AUTOSAR XML (schema 4.0)
standard types defined: float32, float64, sint16, sint32, sint8, uint16, uint32, uint8, void, boolean
package /ImplDataTypes
  7 x impl type, all with category=TYPE_REFERENCE, type-emitter=RTE:
    Impl_IoPositionSensorReadingType: implementation-data-type=uint8
    Impl_IoWeightSensorReadingType: implementation-data-type=uint16
    Impl_MultiStateBtnType: implementation-data-type=uint8
    Impl_SeatModeBtnType: implementation-data-type=uint8
    Impl_SensorPositionType: implementation-data-type=uint8
    Impl_SensorWeightType: implementation-data-type=uint8
    Impl_StepMotorStepType: implementation-data-type=Impl_MultiStateBtnType
package /MappingSets
  data type mapping set MappingSet: mode-request-type-map{implementation-data-type=uint8, mode-group=SeatCtrlMode}
package /PortInterfaces/ClientServer
  6 x client server interface:
    CsIf_IoGetSensorPosition
      operation Opr_IOGet
        arg Arg_position: type=Impl_IoPositionSensorReadingType, direction=OUT
    CsIf_IoGetSensorWeight
      operation Opr_IOGet
        arg Arg_weight: type=Impl_IoWeightSensorReadingType, direction=OUT
    CsIf_IoSetMotor
      operation Opr_IOSetForward
      operation Opr_IOSetReverse
    CsIf_PositionSensor
      operation Opr_GetPosition
        arg Arg_position: type=Impl_SensorPositionType, direction=OUT
    CsIf_StepMotor
      operation Opr_HeightMotor_Move
        arg Arg_Step: type=Impl_StepMotorStepType, direction=IN
      operation Opr_InclineMotor_Move
        arg Arg_Step: type=Impl_MultiStateBtnType, direction=IN
      operation Opr_SlideMotor_Move
        arg Arg_Step: type=Impl_StepMotorStepType, direction=IN
    CsIf_WeightSensor
      operation Opr_GetWeight
        arg Arg_Weight: type=Impl_SensorWeightType, direction=OUT
package /PortInterfaces/ModeSwitch
  mode switch interface MsIf_SeatCtrlMode
    mode group SeatCtrlMode: type=SeatCtrlMode
  mode declaration group SeatCtrlMode: category=ALPHABETIC_ORDER, initial-mode=INIT, on-transition-value=255
    mode AUTO
    mode INIT
    mode MANUAL
package /PortInterfaces/SenderReceiver
  sender receiver interface SrIf_SeatCtrlBtns
    data DE_HeightBtnState: type=Impl_MultiStateBtnType
    data DE_InclineBtnState: type=Impl_MultiStateBtnType
    data DE_SlideBtnState: type=Impl_MultiStateBtnType
  sender receiver interface SrIf_SeatCtrlData
    data DE_Hight: type=uint8
    data DE_Incline: type=uint8
    data DE_Slide: type=uint8
  sender receiver interface SrIf_SeatModeBtn
    data DE_SeatModeBtn: type=Impl_SeatModeBtnType
package /SoftwareComponents
  10 x swc implementation, all with programming-language=C, sw-version=1.0.0, vendor-id=255:
    Impl_SWC_HMI: behavior=Ibhv_SWC_HMI
      code-descriptors:
        code Code: artifact-descriptors=autosar-engineering-object={short-label=SWC.c, category=SWSRC}
      resource consumption ResourceConsumption
    Impl_SWC_HeightMotor: behavior=Ibhv_SWC_HeightMotor
      code-descriptors:
        code Code: artifact-descriptors=autosar-engineering-object={short-label=SWC.c, category=SWSRC}
      resource consumption ResourceConsumption
    Impl_SWC_HeightSensor: behavior=Ibhv_SWC_HeightSensor
      code-descriptors:
        code Code: artifact-descriptors=autosar-engineering-object={short-label=SWC.c, category=SWSRC}
      resource consumption ResourceConsumption
    Impl_SWC_InclineMotor: behavior=Ibhv_SWC_InclineMotor
      code-descriptors:
        code Code: artifact-descriptors=autosar-engineering-object={short-label=SWC.c, category=SWSRC}
      resource consumption ResourceConsumption
    Impl_SWC_InclineSensor: behavior=Ibhv_SWC_InclineSensor
      code-descriptors:
        code Code: artifact-descriptors=autosar-engineering-object={short-label=SWC.c, category=SWSRC}
      resource consumption ResourceConsumption
    Impl_SWC_IoHwAbs: behavior=Ibhv_SWC_IoHwAbs
      code-descriptors:
        code Code: artifact-descriptors=autosar-engineering-object={short-label=SWC.c, category=SWSRC}
      resource consumption ResourceConsumption
    Impl_SWC_SeatManager: behavior=Ibhv_SWC_SeatManager
      code-descriptors:
        code Code: artifact-descriptors=autosar-engineering-object={short-label=SWC.c, category=SWSRC}
      resource consumption ResourceConsumption
    Impl_SWC_SlideMotor: behavior=Ibhv_SWC_SlideMotor
      code-descriptors:
        code Code: artifact-descriptors=autosar-engineering-object={short-label=SWC.c, category=SWSRC}
      resource consumption ResourceConsumption
    Impl_SWC_SlideSensor: behavior=Ibhv_SWC_SlideSensor
      code-descriptors:
        code Code: artifact-descriptors=autosar-engineering-object={short-label=SWC.c, category=SWSRC}
      resource consumption ResourceConsumption
    Impl_SWC_WeightSensor: behavior=Ibhv_SWC_WeightSensor
      code-descriptors:
        code Code: artifact-descriptors=autosar-engineering-object={short-label=SWC.c, category=SWSRC}
      resource consumption ResourceConsumption
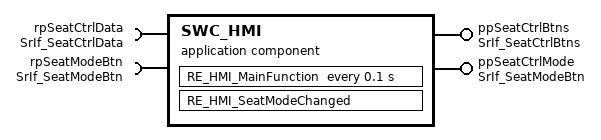
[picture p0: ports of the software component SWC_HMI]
  application sw component type SWC_HMI
    provide port ppSeatCtrlBtns: provided-interface=SrIf_SeatCtrlBtns
    provide port ppSeatCtrlMode: provided-interface=SrIf_SeatModeBtn
    require port rpSeatCtrlData: required-interface=SrIf_SeatCtrlData
    require port rpSeatModeBtn: required-interface=SrIf_SeatModeBtn
    behavior Ibhv_SWC_HMI: data-type-mapping=MappingSet, handle-termination-and-restart=NO-SUPPORT
      data received event DRE_rpSeatModeBtn_DE_SeatModeBtn: start-on-event=RE_HMI_SeatModeChanged, data=rpSeatModeBtn.DE_SeatModeBtn
      timing event TE_RE_HMI_MainFunction_100ms: start-on-event=RE_HMI_MainFunction, period=0.1
      runnable RE_HMI_MainFunction
        data-receive-point-by-arguments:
          access DRP_rpSeatCtrlData_DE_Hight: accessed-variable=rpSeatCtrlData.DE_Hight
          access DRP_rpSeatCtrlData_DE_Incline: accessed-variable=rpSeatCtrlData.DE_Incline
          access DRP_rpSeatCtrlData_DE_Slide: accessed-variable=rpSeatCtrlData.DE_Slide
        data-send-points:
          access DSP_ppSeatCtrlBtns_DE_HeightBtnState: accessed-variable=ppSeatCtrlBtns.DE_HeightBtnState
          access DSP_ppSeatCtrlBtns_DE_InclineBtnState: accessed-variable=ppSeatCtrlBtns.DE_InclineBtnState
          access DSP_ppSeatCtrlBtns_DE_SlideBtnState: accessed-variable=ppSeatCtrlBtns.DE_SlideBtnState
      runnable RE_HMI_SeatModeChanged
        data-receive-point-by-arguments:
          access DRP_rpSeatModeBtn_DE_SeatModeBtn: accessed-variable=rpSeatModeBtn.DE_SeatModeBtn
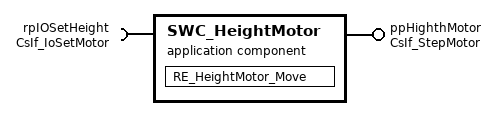
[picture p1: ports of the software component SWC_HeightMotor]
  application sw component type SWC_HeightMotor
    provide port ppHighthMotor: provided-interface=CsIf_StepMotor
    require port rpIOSetHeight: required-interface=CsIf_IoSetMotor
    behavior Ibhv_SWC_HeightMotor: data-type-mapping=MappingSet, handle-termination-and-restart=NO-SUPPORT
      operation invoked event OIE_ppHighthMotor_Opr_HeightMotor_Move: start-on-event=RE_HeightMotor_Move, operation=ppHighthMotor.Opr_HeightMotor_Move
      runnable RE_HeightMotor_Move
        sync call SCP_rpIOSetHeight_Opr_IOSetForward: operation=rpIOSetHeight.Opr_IOSetForward, timeout=0.0
        sync call SCP_rpIOSetHeight_Opr_IOSetReverse: operation=rpIOSetHeight.Opr_IOSetReverse, timeout=0.0
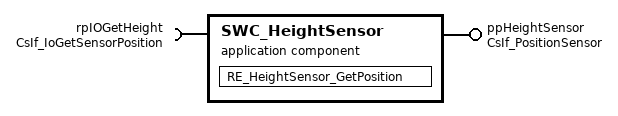
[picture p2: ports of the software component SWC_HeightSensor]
  application sw component type SWC_HeightSensor
    provide port ppHeightSensor: provided-interface=CsIf_PositionSensor
    require port rpIOGetHeight: required-interface=CsIf_IoGetSensorPosition
    behavior Ibhv_SWC_HeightSensor: data-type-mapping=MappingSet, handle-termination-and-restart=NO-SUPPORT
      operation invoked event OIE_ppHeightSensor_Opr_GetPosition: start-on-event=RE_HeightSensor_GetPosition, operation=ppHeightSensor.Opr_GetPosition
      runnable RE_HeightSensor_GetPosition
        sync call SCP_rpIoGetSensorPosition_Opr_IOGet: operation=rpIOGetHeight.Opr_IOGet, timeout=0.0
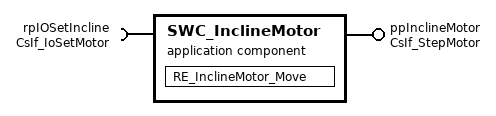
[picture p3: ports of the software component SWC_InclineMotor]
  application sw component type SWC_InclineMotor
    provide port ppInclineMotor: provided-interface=CsIf_StepMotor
    require port rpIOSetIncline: required-interface=CsIf_IoSetMotor
    behavior Ibhv_SWC_InclineMotor: data-type-mapping=MappingSet, handle-termination-and-restart=NO-SUPPORT
      operation invoked event OIE_ppInclineMotor_Opr_InclineMotor_Move: start-on-event=RE_InclineMotor_Move, operation=ppInclineMotor.Opr_InclineMotor_Move
      runnable RE_InclineMotor_Move
        sync call SCP_rpIOSetIncline_Opr_IOSetForward: operation=rpIOSetIncline.Opr_IOSetForward, timeout=0.0
        sync call SCP_rpIOSetIncline_Opr_IOSetReverse: operation=rpIOSetIncline.Opr_IOSetReverse, timeout=0.0
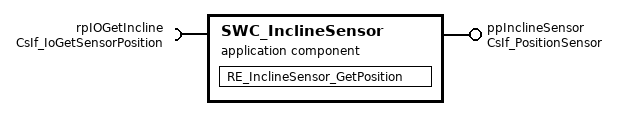
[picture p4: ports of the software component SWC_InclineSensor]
  application sw component type SWC_InclineSensor
    provide port ppInclineSensor: provided-interface=CsIf_PositionSensor
    require port rpIOGetIncline: required-interface=CsIf_IoGetSensorPosition
    behavior Ibhv_SWC_InclineSensor: data-type-mapping=MappingSet, handle-termination-and-restart=NO-SUPPORT
      operation invoked event OIE_ppInclineSensor_Opr_GetPosition: start-on-event=RE_InclineSensor_GetPosition, operation=ppInclineSensor.Opr_GetPosition
      runnable RE_InclineSensor_GetPosition
        sync call SCP_rpIOGetIncline_Opr_IOGet: operation=rpIOGetIncline.Opr_IOGet, timeout=0.0
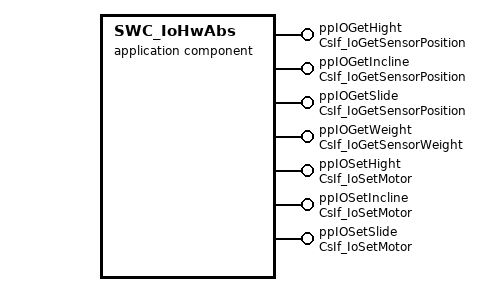
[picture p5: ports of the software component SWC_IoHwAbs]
  application sw component type SWC_IoHwAbs
    7 x provide port:
      ppIOGetHight: provided-interface=CsIf_IoGetSensorPosition
      ppIOGetIncline: provided-interface=CsIf_IoGetSensorPosition
      ppIOGetSlide: provided-interface=CsIf_IoGetSensorPosition
      ppIOGetWeight: provided-interface=CsIf_IoGetSensorWeight
      ppIOSetHight: provided-interface=CsIf_IoSetMotor
      ppIOSetIncline: provided-interface=CsIf_IoSetMotor
      ppIOSetSlide: provided-interface=CsIf_IoSetMotor
    behavior Ibhv_SWC_IoHwAbs: data-type-mapping=MappingSet, handle-termination-and-restart=NO-SUPPORT
      10 x operation invoked event:
        OIE_ppIOGetHight_Opr_IOGet: start-on-event=RE_IoHwAbs_ECUGet_Height, operation=ppIOGetHight.Opr_IOGet
        OIE_ppIOGetIncline_Opr_IOGet: start-on-event=RE_IoHwAbs_ECUGet_Incline, operation=ppIOGetIncline.Opr_IOGet
        OIE_ppIOGetSlide_Opr_IOGet: start-on-event=RE_IoHwAbs_ECUGet_Slide, operation=ppIOGetSlide.Opr_IOGet
        OIE_ppIOGetWeight_Opr_IOGet: start-on-event=RE_IoHwAbs_ECUGet_Weight, operation=ppIOGetWeight.Opr_IOGet
        OIE_ppIOSetHight_Opr_IOSetForward: start-on-event=RE_IoHwAbs_ECUSetForword_Height, operation=ppIOSetHight.Opr_IOSetForward
        OIE_ppIOSetHight_Opr_IOSetReverse: start-on-event=RE_IoHwAbs_ECUSetReverse_Height, operation=ppIOSetHight.Opr_IOSetReverse
        OIE_ppIOSetIncline_Opr_IOSetForward: start-on-event=RE_IoHwAbs_ECUSetForword_Incline, operation=ppIOSetIncline.Opr_IOSetForward
        OIE_ppIOSetIncline_Opr_IOSetReverse: start-on-event=RE_IoHwAbs_ECUSetReverse_Incline, operation=ppIOSetIncline.Opr_IOSetReverse
        OIE_ppIOSetSlide_Opr_IOSetForward: start-on-event=RE_IoHwAbs_ECUSetForword_Slide, operation=ppIOSetSlide.Opr_IOSetForward
        OIE_ppIOSetSlide_Opr_IOSetReverse: start-on-event=RE_IoHwAbs_ECUSetRevese_Slide, operation=ppIOSetSlide.Opr_IOSetReverse
      10 x runnable:
        RE_IoHwAbs_ECUGet_Height
        RE_IoHwAbs_ECUGet_Incline
        RE_IoHwAbs_ECUGet_Slide
        RE_IoHwAbs_ECUGet_Weight
        RE_IoHwAbs_ECUSetForword_Height
        RE_IoHwAbs_ECUSetForword_Incline
        RE_IoHwAbs_ECUSetForword_Slide
        RE_IoHwAbs_ECUSetReverse_Height
        RE_IoHwAbs_ECUSetReverse_Incline
        RE_IoHwAbs_ECUSetRevese_Slide
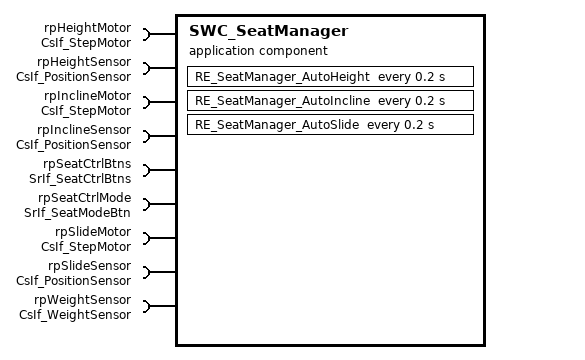
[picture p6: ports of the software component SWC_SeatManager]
  application sw component type SWC_SeatManager
    9 x require port:
      rpHeightMotor: required-interface=CsIf_StepMotor
      rpHeightSensor: required-interface=CsIf_PositionSensor
      rpInclineMotor: required-interface=CsIf_StepMotor
      rpInclineSensor: required-interface=CsIf_PositionSensor
      rpSeatCtrlBtns: required-interface=SrIf_SeatCtrlBtns
      rpSeatCtrlMode: required-interface=SrIf_SeatModeBtn
      rpSlideMotor: required-interface=CsIf_StepMotor
      rpSlideSensor: required-interface=CsIf_PositionSensor
      rpWeightSensor: required-interface=CsIf_WeightSensor
    behavior Ibhv_SWC_SeatManager: data-type-mapping=MappingSet, handle-termination-and-restart=NO-SUPPORT
      data received event DRE_rpSeatCtrlBtns_DE_HeightBtnState: start-on-event=RE_SeatManager_SetHeight, data=rpSeatCtrlBtns.DE_HeightBtnState
      data received event DRE_rpSeatCtrlBtns_DE_InclineBtnState: start-on-event=RE_SeatManager_SetIncline, data=rpSeatCtrlBtns.DE_InclineBtnState
      data received event DRE_rpSeatCtrlBtns_DE_SlideBtnState: start-on-event=RE_SeatManager_SetSlide, data=rpSeatCtrlBtns.DE_SlideBtnState
      timing event TE_RE_SeatManager_AutoHeight_200ms: start-on-event=RE_SeatManager_AutoHeight, period=0.2
      timing event TE_RE_SeatManager_AutoIncline_200ms: start-on-event=RE_SeatManager_AutoIncline, period=0.2
      timing event TE_RE_SeatManager_AutoSlide_200ms: start-on-event=RE_SeatManager_AutoSlide, period=0.2
      6 x runnable:
        RE_SeatManager_AutoHeight
          sync call SCP_rpHeightMotor_Opr_HeightMotor_Move: operation=rpHeightMotor.Opr_HeightMotor_Move, timeout=0.0
          sync call SCP_rpHeightSensor_Opr_GetPosition: operation=rpHeightSensor.Opr_GetPosition, timeout=0.0
          sync call SCP_rpWeightSensor_Opr_GetWeight: operation=rpWeightSensor.Opr_GetWeight, timeout=0.0
        RE_SeatManager_AutoIncline
          sync call SCP_rpInclineMotor_Opr_InclineMotor_Move: operation=rpInclineMotor.Opr_InclineMotor_Move, timeout=0.0
          sync call SCP_rpInclineSensor_Opr_GetPosition: operation=rpInclineSensor.Opr_GetPosition, timeout=0.0
          sync call SCP_rpWeightSensor_Opr_GetWeight: operation=rpWeightSensor.Opr_GetWeight, timeout=0.0
        RE_SeatManager_AutoSlide
          sync call SCP_rpSlideMotor_Opr_SlideMotor_Move: operation=rpSlideMotor.Opr_SlideMotor_Move, timeout=0.0
          sync call SCP_rpSlideSensor_Opr_GetPosition: operation=rpSlideSensor.Opr_GetPosition, timeout=0.0
          sync call SCP_rpWeightSensor_Opr_GetWeight: operation=rpWeightSensor.Opr_GetWeight, timeout=0.0
        RE_SeatManager_SetHeight
          data-receive-point-by-arguments:
            access DRP_rpSeatCtrlBtns_DE_HeightBtnState: accessed-variable=rpSeatCtrlBtns.DE_HeightBtnState
          sync call SCP_rpHeightMotor_Opr_HeightMotor_Move: operation=rpHeightMotor.Opr_HeightMotor_Move, timeout=0.0
        RE_SeatManager_SetIncline
          data-receive-point-by-arguments:
            access DRP_rpSeatCtrlBtns_DE_InclineBtnState: accessed-variable=rpSeatCtrlBtns.DE_InclineBtnState
          sync call SCP_rpInclineMotor_Opr_InclineMotor_Move: operation=rpInclineMotor.Opr_InclineMotor_Move, timeout=0.0
        RE_SeatManager_SetSlide
          data-receive-point-by-arguments:
            access DRP_rpSeatCtrlBtns_DE_SlideBtnState: accessed-variable=rpSeatCtrlBtns.DE_SlideBtnState
          sync call SCP_rpSlideMotor_Opr_SlideMotor_Move: operation=rpSlideMotor.Opr_SlideMotor_Move, timeout=0.0
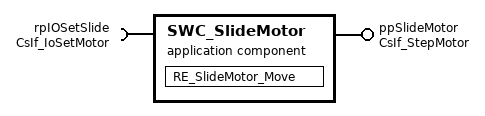
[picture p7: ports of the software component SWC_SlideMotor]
  application sw component type SWC_SlideMotor
    provide port ppSlideMotor: provided-interface=CsIf_StepMotor
    require port rpIOSetSlide: required-interface=CsIf_IoSetMotor
    behavior Ibhv_SWC_SlideMotor: data-type-mapping=MappingSet, handle-termination-and-restart=NO-SUPPORT
      operation invoked event OIE_ppSlideMotor_Opr_SlideMotor_Move: start-on-event=RE_SlideMotor_Move, operation=ppSlideMotor.Opr_SlideMotor_Move
      runnable RE_SlideMotor_Move
        sync call SCP_rpIOSetSlide_Opr_IOSetForward: operation=rpIOSetSlide.Opr_IOSetForward, timeout=0.0
        sync call SCP_rpIOSetSlide_Opr_IOSetReverse: operation=rpIOSetSlide.Opr_IOSetReverse, timeout=0.0
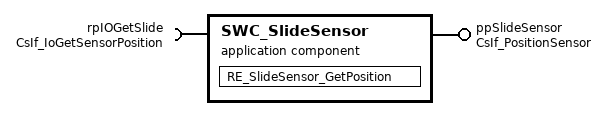
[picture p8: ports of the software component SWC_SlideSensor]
  application sw component type SWC_SlideSensor
    provide port ppSlideSensor: provided-interface=CsIf_PositionSensor
    require port rpIOGetSlide: required-interface=CsIf_IoGetSensorPosition
    behavior Ibhv_SWC_SlideSensor: data-type-mapping=MappingSet, handle-termination-and-restart=NO-SUPPORT
      operation invoked event OIE_ppSlideSensor_Opr_GetPosition: start-on-event=RE_SlideSensor_GetPosition, operation=ppSlideSensor.Opr_GetPosition
      runnable RE_SlideSensor_GetPosition
        sync call SCP_rpIOGetSlide_Opr_IOGet: operation=rpIOGetSlide.Opr_IOGet, timeout=0.0
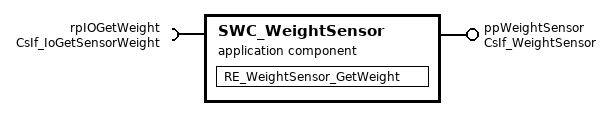
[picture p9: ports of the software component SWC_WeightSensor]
  application sw component type SWC_WeightSensor
    provide port ppWeightSensor: provided-interface=CsIf_WeightSensor
    require port rpIOGetWeight: required-interface=CsIf_IoGetSensorWeight
    behavior Ibhv_SWC_WeightSensor: data-type-mapping=MappingSet, handle-termination-and-restart=NO-SUPPORT
      operation invoked event OIE_ppWeightSensor_Opr_GetWeight: start-on-event=RE_WeightSensor_GetWeight, operation=ppWeightSensor.Opr_GetWeight
      runnable RE_WeightSensor_GetWeight
        sync call SCP_rpIOGetWeight_Opr_IOGet: operation=rpIOGetWeight.Opr_IOGet, timeout=0.0
package /Compositions
  composition sw component type SeatCtrlComposition
    10 x component:
      SWC_HMI: type=SWC_HMI
      SWC_HeightMotor: type=SWC_HeightMotor
      SWC_HeightSensor: type=SWC_HeightSensor
      SWC_InclineMotor: type=SWC_InclineMotor
      SWC_InclineSensor: type=SWC_InclineSensor
      SWC_IoHwAbs: type=SWC_IoHwAbs
      SWC_SeatManager: type=SWC_SeatManager
      SWC_SlideMotor: type=SWC_SlideMotor
      SWC_SlideSensor: type=SWC_SlideSensor
      SWC_WeightSensor: type=SWC_WeightSensor
    connect SWC_HMI.ppSeatCtrlBtns -> SWC_SeatManager.rpSeatCtrlBtns
    connect SWC_HMI.ppSeatCtrlMode -> SWC_SeatManager.rpSeatCtrlMode
    connect SWC_HeightMotor.ppHighthMotor -> SWC_SeatManager.rpHeightMotor
    connect SWC_HeightSensor.ppHeightSensor -> SWC_SeatManager.rpHeightSensor
    connect SWC_InclineMotor.ppInclineMotor -> SWC_SeatManager.rpInclineMotor
    connect SWC_InclineSensor.ppInclineSensor -> SWC_SeatManager.rpInclineSensor
    connect SWC_IoHwAbs.ppIOGetHight -> SWC_HeightSensor.rpIOGetHeight
    connect SWC_IoHwAbs.ppIOGetSlide -> SWC_SlideSensor.rpIOGetSlide
    connect SWC_IoHwAbs.ppIOGetWeight -> SWC_WeightSensor.rpIOGetWeight
    connect SWC_IoHwAbs.ppIOSetHight -> SWC_HeightMotor.rpIOSetHeight
    connect SWC_IoHwAbs.ppIOSetIncline -> SWC_InclineMotor.rpIOSetIncline
    connect SWC_IoHwAbs.ppIOSetIncline -> SWC_InclineSensor.rpIOGetIncline
    connect SWC_IoHwAbs.ppIOSetSlide -> SWC_SlideMotor.rpIOSetSlide
    connect SWC_SlideMotor.ppSlideMotor -> SWC_SeatManager.rpSlideMotor
    connect SWC_SlideSensor.ppSlideSensor -> SWC_SeatManager.rpSlideSensor
    connect SWC_WeightSensor.ppWeightSensor -> SWC_SeatManager.rpWeightSensor
